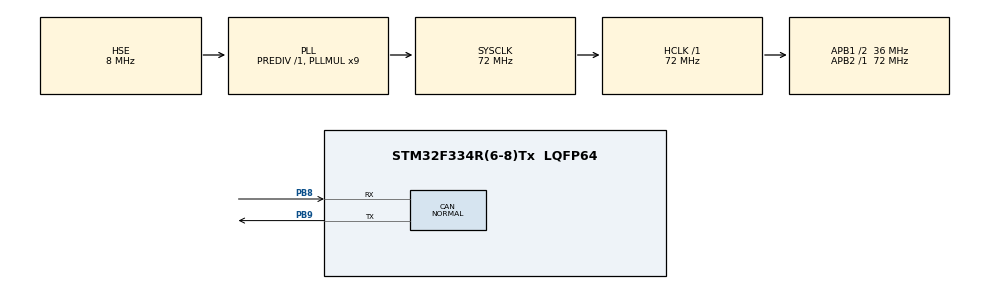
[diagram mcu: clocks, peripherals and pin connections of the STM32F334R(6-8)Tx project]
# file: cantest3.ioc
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CAN.ABOM=DISABLE
CAN.AWUM=DISABLE
CAN.BS1=CAN_BS1_16TQ
CAN.CalculateTimeQuantum=444.44444444444446
CAN.Mode=CAN_MODE_NORMAL
CAN.NART=DISABLE
CAN.RFLM=ENABLE
CAN.SJW=CAN_SJW_1TQ
CAN.TXFP=DISABLE
Mcu.Family=STM32F3
Mcu.Name=STM32F334R(6-8)Tx
Mcu.Package=LQFP64
NVIC.CAN_RX0_IRQn=true\:0\:0\:false\:true\:true\:1\:true
NVIC.PriorityGroup=NVIC_PRIORITYGROUP_4
NVIC.TIM7_DAC2_IRQn=true\:0\:0\:false\:true\:true\:2\:true
PA13.Mode=Serial_Wire
PA13.Signal=SYS_JTMS-SWDIO
PA14.Mode=Serial_Wire
PA14.Signal=SYS_JTCK-SWCLK
PB8.GPIO_PuPd=GPIO_PULLUP
PB8.Mode=Master
PB8.Signal=CAN_RX
PB9.Mode=Master
PB9.Signal=CAN_TX
PC14\ /\ OSC32_IN.Mode=LSE-External-Oscillator
PC14\ /\ OSC32_IN.Signal=RCC_OSC32_IN
PC15\ /\ OSC32_OUT.Mode=LSE-External-Oscillator
PC15\ /\ OSC32_OUT.Signal=RCC_OSC32_OUT
PF0\ /\ OSC_IN.Mode=HSE-External-Oscillator
PF0\ /\ OSC_IN.Signal=RCC_OSC_IN
PF1\ /\ OSC_OUT.Mode=HSE-External-Oscillator
PF1\ /\ OSC_OUT.Signal=RCC_OSC_OUT
ProjectManager.HeapSize=0x200
ProjectManager.StackSize=0x400
ProjectManager.TargetToolchain=MDK-ARM V5
RCC.AHBFreq_Value=72000000
RCC.APB1CLKDivider=RCC_HCLK_DIV2
RCC.APB1Freq_Value=36000000
RCC.APB1TimFreq_Value=72000000
RCC.APB2Freq_Value=72000000
RCC.APB2TimFreq_Value=72000000
RCC.CortexFreq_Value=72000000
RCC.HCLKFreq_Value=72000000
RCC.HSE_VALUE=8000000
RCC.HSI_VALUE=8000000
RCC.PLLMUL=RCC_PLL_MUL9
RCC.PLLSourceVirtual=RCC_PLLSOURCE_HSE
RCC.SYSCLKFreq_VALUE=72000000
RCC.SYSCLKSourceVirtual=RCC_SYSCLKSOURCE_PLLCLK
TIM7.AutoReloadPreload=TIM_AUTORELOAD_PRELOAD_ENABLE
TIM7.Period=10000
TIM7.Prescaler=7200-1
TIM7.TIM_MasterOutputTrigger=TIM_TRGO_UPDATE
VP_TIM7_VS_ClockSourceINT.Mode=Enable_Timer
board=custom

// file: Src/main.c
/* USER CODE BEGIN Header */
/**
  ******************************************************************************
  * @file           : main.c
  * @brief          : Main program body
  ******************************************************************************
  ** This notice applies to any and all portions of this file
  * that are not between comment pairs USER CODE BEGIN and
  * USER CODE END. Other portions of this file, whether
  * inserted by the user or by software development tools
  * are owned by their respective copyright owners.
  *
  * COPYRIGHT(c) 2019 STMicroelectronics
  *
  * Redistribution and use in source and binary forms, with or without modification,
  * are permitted provided that the following conditions are met:
  *   1. Redistributions of source code must retain the above copyright notice,
  *      this list of conditions and the following disclaimer.
  *   2. Redistributions in binary form must reproduce the above copyright notice,
  *      this list of conditions and the following disclaimer in the documentation
  *      and/or other materials provided with the distribution.
  *   3. Neither the name of STMicroelectronics nor the names of its contributors
  *      may be used to endorse or promote products derived from this software
  *      without specific prior written permission.
  *
  * THIS SOFTWARE IS PROVIDED BY THE COPYRIGHT HOLDERS AND CONTRIBUTORS "AS IS"
  * AND ANY EXPRESS OR IMPLIED WARRANTIES, INCLUDING, BUT NOT LIMITED TO, THE
  * IMPLIED WARRANTIES OF MERCHANTABILITY AND FITNESS FOR A PARTICULAR PURPOSE ARE
  * DISCLAIMED. IN NO EVENT SHALL THE COPYRIGHT HOLDER OR CONTRIBUTORS BE LIABLE
  * FOR ANY DIRECT, INDIRECT, INCIDENTAL, SPECIAL, EXEMPLARY, OR CONSEQUENTIAL
  * DAMAGES (INCLUDING, BUT NOT LIMITED TO, PROCUREMENT OF SUBSTITUTE GOODS OR
  * SERVICES; LOSS OF USE, DATA, OR PROFITS; OR BUSINESS INTERRUPTION) HOWEVER
  * CAUSED AND ON ANY THEORY OF LIABILITY, WHETHER IN CONTRACT, STRICT LIABILITY,
  * OR TORT (INCLUDING NEGLIGENCE OR OTHERWISE) ARISING IN ANY WAY OUT OF THE USE
  * OF THIS SOFTWARE, EVEN IF ADVISED OF THE POSSIBILITY OF SUCH DAMAGE.
  *
  ******************************************************************************
  */
/* USER CODE END Header */

#include "main.h"
#include "can.h"
#include "tim.h"
#include "gpio.h"

/* USER CODE BEGIN PV */
extern CAN_TxHeaderTypeDef TxMsg;
extern uint8_t TR_BUF[8];
uint8_t Cnt;
/* USER CODE END PV */

void SystemClock_Config(void);
static void MX_NVIC_Init(void);

int main(void)
{
  /* USER CODE BEGIN 1 */
	while(Cnt<8)
	{
		TR_BUF[Cnt] = Cnt;
		Cnt++;
	}

  /* USER CODE END 1 */

  /* MCU Configuration--------------------------------------------------------*/

  /* Reset of all peripherals, Initializes the Flash interface and the Systick. */
  HAL_Init();

  /* Configure the system clock */
  SystemClock_Config();

  /* Initialize all configured peripherals */
  MX_GPIO_Init();
  MX_CAN_Init();
  MX_TIM7_Init();

  /* Initialize interrupts */
  MX_NVIC_Init();
  /* USER CODE BEGIN 2 */
	HAL_TIM_Base_Start_IT(&htim7);
	CAN_TxMsgConfig();
	CAN_Pass_Filter_init();
	HAL_CAN_Start(&hcan);
	HAL_CAN_ActivateNotification(&hcan, CAN_IT_RX_FIFO0_MSG_PENDING);

	//CAN_TRANSMIT();
  /* USER CODE END 2 */

  /* Infinite loop */
  while (1)
  {

  }
}

void SystemClock_Config(void)
{
  RCC_OscInitTypeDef RCC_OscInitStruct = {0};
  RCC_ClkInitTypeDef RCC_ClkInitStruct = {0};

  /**Initializes the CPU, AHB and APB busses clocks
  */
  RCC_OscInitStruct.OscillatorType = RCC_OSCILLATORTYPE_HSE;
  RCC_OscInitStruct.HSEState = RCC_HSE_ON;
  RCC_OscInitStruct.HSEPredivValue = RCC_HSE_PREDIV_DIV1;
  RCC_OscInitStruct.HSIState = RCC_HSI_ON;
  RCC_OscInitStruct.PLL.PLLState = RCC_PLL_ON;
  RCC_OscInitStruct.PLL.PLLSource = RCC_PLLSOURCE_HSE;
  RCC_OscInitStruct.PLL.PLLMUL = RCC_PLL_MUL9;
  if (HAL_RCC_OscConfig(&RCC_OscInitStruct) != HAL_OK)
  {
    Error_Handler();
  }
  /**Initializes the CPU, AHB and APB busses clocks
  */
  RCC_ClkInitStruct.ClockType = RCC_CLOCKTYPE_HCLK|RCC_CLOCKTYPE_SYSCLK
                              |RCC_CLOCKTYPE_PCLK1|RCC_CLOCKTYPE_PCLK2;
  RCC_ClkInitStruct.SYSCLKSource = RCC_SYSCLKSOURCE_PLLCLK;
  RCC_ClkInitStruct.AHBCLKDivider = RCC_SYSCLK_DIV1;
  RCC_ClkInitStruct.APB1CLKDivider = RCC_HCLK_DIV2;
  RCC_ClkInitStruct.APB2CLKDivider = RCC_HCLK_DIV1;

  if (HAL_RCC_ClockConfig(&RCC_ClkInitStruct, FLASH_LATENCY_2) != HAL_OK)
  {
    Error_Handler();
  }
}

/**
  * @brief NVIC Configuration.
  * @retval None
  */
static void MX_NVIC_Init(void)
{
  /* CAN_RX0_IRQn interrupt configuration */
  HAL_NVIC_SetPriority(CAN_RX0_IRQn, 0, 0);
  HAL_NVIC_EnableIRQ(CAN_RX0_IRQn);
  /* TIM7_DAC2_IRQn interrupt configuration */
  HAL_NVIC_SetPriority(TIM7_DAC2_IRQn, 0, 0);
  HAL_NVIC_EnableIRQ(TIM7_DAC2_IRQn);
}

void Error_Handler(void)
{
}

/************************ (C) COPYRIGHT STMicroelectronics *****END OF FILE****/
